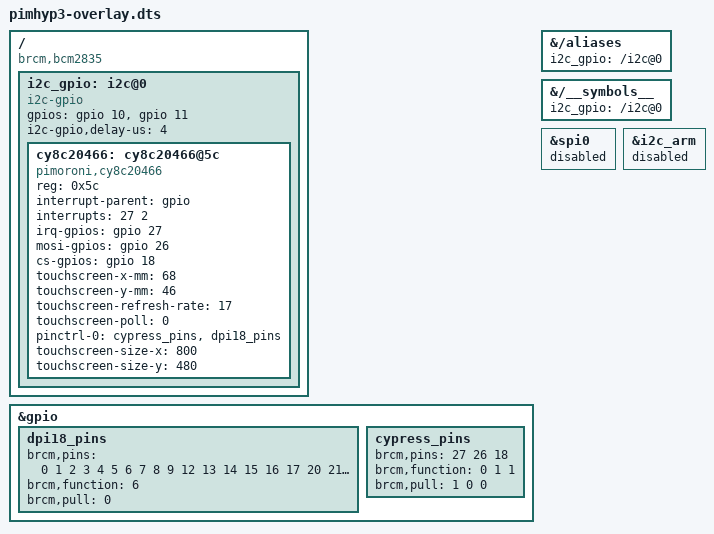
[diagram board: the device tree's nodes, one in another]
/*
 * Device tree overlay for Cypress Cy8c20466 Touchscreen and & Pimoroni Hyperpixel3.5" LCD
 * V2
 *
 * Compile:
 * dtc -@ -I dts -O dtb -o pimhyp3.dtbo pimhyp3-overlay.dts
 */

/dts-v1/;
/plugin/;

/{
    /* Identify the RPi models this is compatible with (is this sufficient?) */
    compatible = "brcm,bcm2835", "brcm,bcm2836", "brcm,bcm2708", "brcm,bcm2709";

    /* Define a group of pins to be configured by the GPIO driver as function 6 = ALT2 = DPI mode */
    fragment@0 {
        target = <&gpio>;
        __overlay__ {
            dpi18_pins: dpi18_pins {
                brcm,pins = <0 1 2 3 4 5 6 7 8 9 12 13 14 15 16 17 20 21 22 23 24 25>;
                brcm,function = <6>;
                brcm,pull = <0>;
            };
        };
    };


    /* Define cypress_pins as child of gpio group */
    /* referenced by pinctrl to set up gpio 27 as input with pull-down */
    fragment@1 {
        target = <&gpio>;
        __overlay__ {
            cypress_pins: cypress_pins {
                brcm,pins = <27 26 18 >; // IRQ, Mosi, CS
                brcm,function = <0 1 1>; // in out out
                brcm,pull = <1 0 0>; // pull-down, none, none?
            };
        };
    };

    /* Create i2c-gpio driver instance for software i2c on gpio 10 & 11 as i2c-3. 4us delay for 100kHz */
    fragment@2 {
        target-path = "/";
        __overlay__ {
            i2c_gpio: i2c@0 {
                compatible = "i2c-gpio";
                gpios = <&gpio 10 0 /* sda */
                         &gpio 11 0 /* scl */
                        >;
                i2c-gpio,delay-us = <4>;
                #address-cells = <1>;
                #size-cells = <0>;
            };
        };
    };

    /* Add the touchscreen controller as a device under i2c_gpio (for default case) */
    fragment@3 {
        target = <&i2c_gpio>;
        __overlay__ {
            /* needed to avoid dtc warning */
            #address-cells = <1>;
            #size-cells = <0>;
            cy8c20466: cy8c20466@5c {
                compatible = "pimoroni,cy8c20466";
                reg = <0x5c>;
                interrupt-parent = <&gpio>;
                interrupts = <27 2>;
                irq-gpios  = <&gpio 27 0>; // specify  GPIO27 as the irq line from the TS controller, CLK from LCD
                mosi-gpios = <&gpio 26 0>; // specify  GPIO26 as the mosi line from the LCD controller
                cs-gpios   = <&gpio 18 0>; // specify  GPIO27 as the cs line from the LCD controller
                touchscreen-x-mm = <68>;
                touchscreen-y-mm = <46>;
                touchscreen-refresh-rate = <17>;
                touchscreen-poll = <0>;
            };
        };
    };

    /* Define a group of pins to be configured by the GPIO driver as function 6 = ALT2 = DPI mode */
    /* THIS IS AN ALTERNATIVE GROUP WHERE ARGON FAN IS FITTED, REMOVING GPIO 0&1 from GROUP */
    fragment@4 {
        target = <&cy8c20466>;
        __overlay__ {
                pinctrl-names = "default";
                pinctrl-0 = <&cypress_pins &dpi18_pins>;
        };
    };

    /* Add the touchscreen controller as a device under i2c_gpio (For check-only)*/
    fragment@5 {
        target = <&cy8c20466>;
        __dormant__ {
                pinctrl-names = "default";
                pinctrl-0 = <&cypress_pins>;
                touchscreen-check;              //Indicate to driver that we are just checking presence.
        };
    };

/////////////////////////////////////////////////////////////////

    /* display_lcd_rotate=0 */
    /* Portrait, USB ports on top */
    fragment@6 {
        target = <&cy8c20466>;
        __overlay__ {
            touchscreen-size-x = <800>;
            touchscreen-size-y = <480>;
        };
    };

    /* display_lcd_rotate=1 */
    /* Landscape, USB ports on left */
    fragment@7 {
        target = <&cy8c20466>;
        __dormant__ {
            touchscreen-inverted-y;
            touchscreen-swapped-x-y;
            touchscreen-size-x = <480>;
            touchscreen-size-y = <800>;
        };
    };

    /* display_lcd_rotate=2 */
    /* Portrait, USB ports on bottom */
    fragment@8 {
        target = <&cy8c20466>;
        __dormant__ {
            touchscreen-inverted-y;
            touchscreen-inverted-x;
            touchscreen-size-x = <800>;
            touchscreen-size-y = <480>;
        };
    };

    /* display_lcd_rotate=3 */
    /* Landscape, USB ports on right */
    fragment@9 {
        target = <&cy8c20466>;
        __dormant__ {
            touchscreen-swapped-x-y;
            touchscreen-inverted-x;
            touchscreen-size-x = <480>;
            touchscreen-size-y = <800>;
        };
    };
/////////////////////////////////////////////////////////////////////



    fragment@10 {
        target-path = "/aliases";
        __overlay__ {
            i2c_gpio = "/i2c@0";
        };
    };

    fragment@11 {
        target-path = "/__symbols__";
        __overlay__ {
            i2c_gpio = "/i2c@0";
        };
    };

    /* Disable SPI - because DPI uses it. Not necessary, just in case */
    fragment@12 {
        target = <&spi0>;
        __overlay__ {
            status = "disabled";
        };
    };

    /* Disable i2c_arm - because DPI uses it. Not necessary, just in case */
    fragment@13 {
        target = <&i2c_arm>;
        __overlay__ {
            status = "disabled";
        };
    };

	__overrides__ {
        x-invert = <&cy8c20466>, "touchscreen-inverted-x:0";
        y-invert = <&cy8c20466>, "touchscreen-inverted-y:0";
        xy-swap  = <&cy8c20466>, "touchscreen-swapped-x-y:0";
        x-size   = <&cy8c20466>, "touchscreen-size-x:0";
        y-size   = <&cy8c20466>, "touchscreen-size-y:0";
        x2y      = <&cy8c20466>, "touchscreen-x2y:0";
        refresh-rate = <&cy8c20466>, "touchscreen-refresh-rate:0";
        poll     = <&cy8c20466>, "touchscreen-use-poll:0";
        rotate   = <0>,"+6-7-8-9";
        rotate_0 = <0>,"+6-7-8-9";
        rotate_1 = <0>,"-6+7-8-9";
        rotate_2 = <0>,"-6-7+8-9";
        rotate_3 = <0>,"-6-7-8+9";
        checkonly= <0>,"-4+5-6-7-8-9-10";
	};
};
